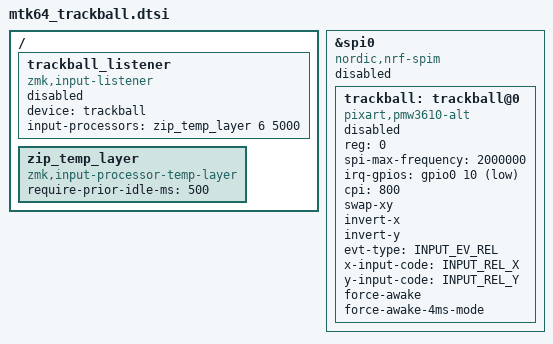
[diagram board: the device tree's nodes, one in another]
#include <zephyr/dt-bindings/input/input-event-codes.h>
#include <input/processors.dtsi>

&spi0 {
    status = "disabled";
    compatible = "nordic,nrf-spim";

    trackball: trackball@0 {
        status = "disabled";
        compatible = "pixart,pmw3610-alt";
        reg = <0>;
        spi-max-frequency = <2000000>;
        irq-gpios = <&gpio0 10 (GPIO_ACTIVE_LOW | GPIO_PULL_UP)>;
        cpi = <800>;

        swap-xy;
        invert-x;
        invert-y;

        evt-type = <INPUT_EV_REL>;
        x-input-code = <INPUT_REL_X>;
        y-input-code = <INPUT_REL_Y>;

        force-awake;
        force-awake-4ms-mode;
    };
};

/ {
    trackball_listener: trackball_listener {
        compatible = "zmk,input-listener";
        status = "disabled";
        device = <&trackball>;

        input-processors = <&zip_temp_layer 6 5000>;
    };

    zip_temp_layer: zip_temp_layer {
        compatible = "zmk,input-processor-temp-layer";
        #input-processor-cells = <2>;
        require-prior-idle-ms = <500>;
    };
};
